# haltium_secure register map
Vendor: Nordic Semiconductor; Series: nRFHaltium; File version: 1
CPU: CM33 r0p4, little endian, MPU, FPU, 3 interrupt priority bits, 480 interrupts
Registers are 32-bit, read-write, reset 0x0 unless marked. A register's access mark holds for its fields unless they carry their own. Offsets are from the block's base; [hi:lo] are bit positions; lines under a group give offsets from that group; 'fields as' and 'values as' point back to an identical list.

## GLOBAL_GGENERIC59_NS — GENERIC 0
Base 0xBF001000
Same registers: GENERIC1_NS 0x41006000, GLOBAL_GGENERIC55_NS 0x4F8D3000, GLOBAL_GGENERIC56_NS 0x4F8D4000, GLOBAL_GGENERIC57_NS 0x4F8D5000, GLOBAL_GGENERIC58_NS 0x4F8D6000, GENERIC0_S 0x51002000, GENERIC1_S 0x51006000, GENERIC2_S 0x5100A000, GENERIC3_S 0x5100B000, GENERIC6_S 0x5100F000, GENERIC7_S 0x5101C000, GENERIC8_S 0x5101D000, GENERIC10_S 0x5101F000, GLOBAL_GGENERIC55_S 0x5F8D3000, GLOBAL_GGENERIC56_S 0x5F8D4000, GLOBAL_GGENERIC57_S 0x5F8D5000, GLOBAL_GGENERIC58_S 0x5F8D6000, GLOBAL_GGENERIC59_S 0xBF001000 (alternate view of GLOBAL_GGENERIC59_NS), GLOBAL_GGENERIC60_NS 0xBF003000, GLOBAL_GGENERIC60_S 0xBF003000 (alternate view of GLOBAL_GGENERIC60_NS), GGENERIC0_S 0xBF004000, GGENERIC61_S 0xBF007000, GLOBAL_TSGEN_NS 0xBF041000, GLOBAL_ETB_NS 0xBF044000, GLOBAL_ETR_NS 0xBF045000, GENERIC11_S 0xE0042000
0x00 TASKS_GENERICTASK wo — Generic event
  [0] TASKS_GENERICTASK
    1=Trigger task
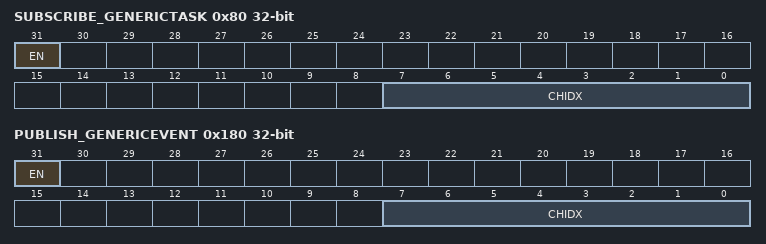
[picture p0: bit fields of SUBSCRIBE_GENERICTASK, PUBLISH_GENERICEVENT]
0x80 SUBSCRIBE_GENERICTASK — Subscribe configuration for task GENERICTASK
  [31] EN
    0=Disabled (Disable subscription); 1=Enabled (Enable subscription)
  [7:0] CHIDX — DPPI channel that task GENERICTASK will subscribe to
0x100 EVENTS_GENERICEVENT — Generic event
  [0] EVENTS_GENERICEVENT
    0=NotGenerated (Event not generated); 1=Generated (Event generated)
0x180 PUBLISH_GENERICEVENT — Publish configuration for event GENERICEVENT
  [31] EN
    0=Disabled (Disable publishing); 1=Enabled (Enable publishing)
  [7:0] CHIDX — DPPI channel that event GENERICEVENT will publish to
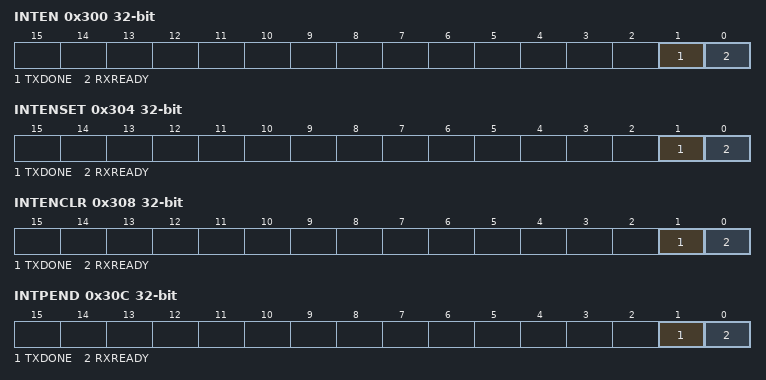
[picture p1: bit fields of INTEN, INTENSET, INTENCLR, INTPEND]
0x300 INTEN — Enable or disable interrupt
  [0] GENERICEVENT — Enable or disable interrupt for event GENERICEVENT
    0=Disabled; 1=Enabled
0x304 INTENSET — Enable interrupt
  [0] GENERICEVENT — Write '1' to enable interrupt for event GENERICEVENT
    on read: 0=Disabled (Read: Disabled); 1=Enabled (Read: Enabled) | on write: 1=Set (Enable)
0x308 INTENCLR — Disable interrupt
  [0] GENERICEVENT — Write '1' to disable interrupt for event GENERICEVENT
    on read: 0=Disabled (Read: Disabled); 1=Enabled (Read: Enabled) | on write: 1=Clear (Disable)

## CTRLAP_S — Control access port
Base 0xBF002000
0x100 EVENTS_RXREADY — The RXSTATUS is changed to DataPending
  [0] EVENTS_RXREADY
    0=NotGenerated (Event not generated); 1=Generated (Event generated)
0x104 EVENTS_TXDONE — The TXSTATUS is changed to NoDataPending
  [0] EVENTS_TXDONE
    values as EVENTS_RXREADY.EVENTS_RXREADY
0x300 INTEN — Enable or disable interrupt
  [1] TXDONE — Enable or disable interrupt for event TXDONE
    0=Disabled; 1=Enabled
  [0] RXREADY — Enable or disable interrupt for event RXREADY
    0=Disabled; 1=Enabled
0x304 INTENSET — Enable interrupt
  [1] TXDONE — Write '1' to enable interrupt for event TXDONE
    on read: 0=Disabled (Read: Disabled); 1=Enabled (Read: Enabled) | on write: 1=Set (Enable)
  [0] RXREADY — Write '1' to enable interrupt for event RXREADY
    values as TXDONE
0x308 INTENCLR — Disable interrupt
  [1] TXDONE — Write '1' to disable interrupt for event TXDONE
    on read: 0=Disabled (Read: Disabled); 1=Enabled (Read: Enabled) | on write: 1=Clear (Disable)
  [0] RXREADY — Write '1' to disable interrupt for event RXREADY
    values as TXDONE
0x30C INTPEND ro — Pending interrupts
  [1] TXDONE — Read pending status of interrupt for event TXDONE
    on read: 0=NotPending (Read: Not pending); 1=Pending (Read: Pending)
  [0] RXREADY — Read pending status of interrupt for event RXREADY
    values as TXDONE
0x400 MAILBOX group — Unspecified
  0x00 RXDATA ro — Data sent from the debugger to the CPU
    [31:0] RXDATA — Data received from debugger
  0x04 RXSTATUS ro — Status to indicate if data sent from the debugger to the CPU has been read
    [0] RXSTATUS — Status of data in register RXDATA
      0=No data pending in register RXDATA; 1=Data pending in register RXDATA
  0x80 TXDATA — Data sent from the CPU to the debugger
    [31:0] TXDATA — Data sent to debugger
  0x84 TXSTATUS ro — Status to indicate if data sent from the CPU to the debugger has been read
    [0] TXSTATUS — Status of data in register TXDATA
      0=No data pending in register TXDATA; 1=Data pending in register TXDATA
  0x88 BOOTMODE ro — Secure domain boot mode.
    [0] MODE
      0=Normal mode of operation; 1=ROM operation mode
0x500 INFO group — Unspecified
  0x00 PARTNO — Part number of the device
    [31:0] PARTNO — Part number
  0x04 HWREVISION — Hardware Revision of the device
    [31:0] ID — Part Variant
  0x08 READY reset 0x1 — The INFO registers ready status.
    [0] READY — Ready status.
      0=Ready; 1=NotReady (Not reday)
